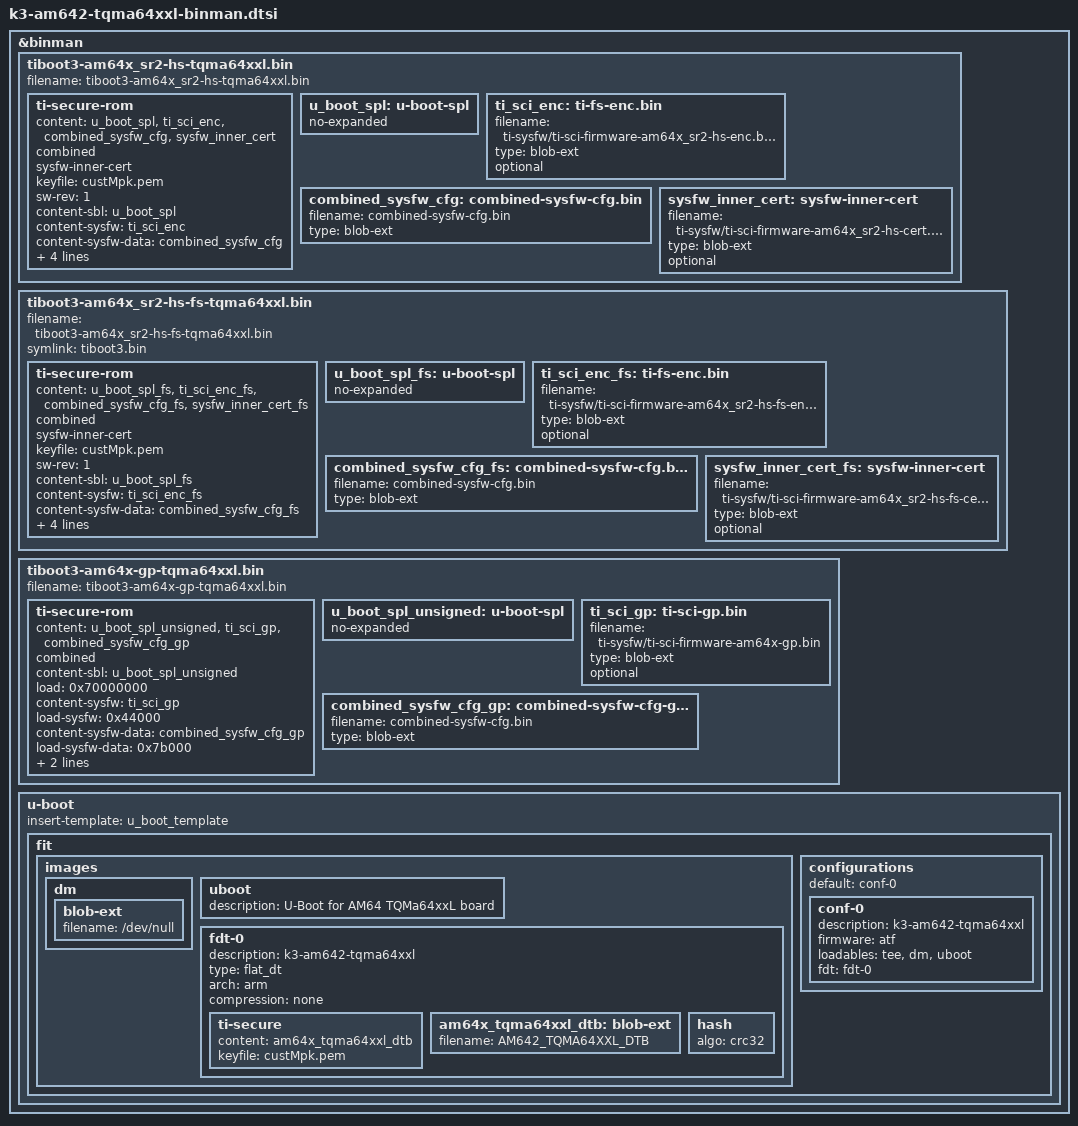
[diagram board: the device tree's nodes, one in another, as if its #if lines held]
// SPDX-License-Identifier: GPL-2.0-or-later
/*
 * Copyright (C) 2022 Texas Instruments Incorporated - https://www.ti.com/
 * Copyright (c) 2023-2025 TQ-Systems GmbH <u-boot@ew.tq-group.com>, D-82229 Seefeld, Germany.
 * Author: Matthias Schiffer
 */

#include "k3-binman.dtsi"

#if IS_ENABLED(CONFIG_TARGET_AM64_R5_TQMA64XXL)

&binman {
	tiboot3-am64x_sr2-hs-tqma64xxl.bin {
		filename = "tiboot3-am64x_sr2-hs-tqma64xxl.bin";
		ti-secure-rom {
			content = <&u_boot_spl>, <&ti_sci_enc>,
				<&combined_sysfw_cfg>, <&sysfw_inner_cert>;
			combined;
			sysfw-inner-cert;
			keyfile = "custMpk.pem";
			sw-rev = <1>;
			content-sbl = <&u_boot_spl>;
			content-sysfw = <&ti_sci_enc>;
			content-sysfw-data = <&combined_sysfw_cfg>;
			content-sysfw-inner-cert = <&sysfw_inner_cert>;
			load = <0x70000000>;
			load-sysfw = <0x44000>;
			load-sysfw-data = <0x7b000>;
		};
		u_boot_spl: u-boot-spl {
			no-expanded;
		};
		ti_sci_enc: ti-fs-enc.bin {
			filename = "ti-sysfw/ti-sci-firmware-am64x_sr2-hs-enc.bin";
			type = "blob-ext";
			optional;
		};
		combined_sysfw_cfg: combined-sysfw-cfg.bin {
			filename = "combined-sysfw-cfg.bin";
			type = "blob-ext";
		};
		sysfw_inner_cert: sysfw-inner-cert {
			filename = "ti-sysfw/ti-sci-firmware-am64x_sr2-hs-cert.bin";
			type = "blob-ext";
			optional;
		};

	};
};

&binman {
	tiboot3-am64x_sr2-hs-fs-tqma64xxl.bin {
		filename = "tiboot3-am64x_sr2-hs-fs-tqma64xxl.bin";
		symlink = "tiboot3.bin";
		ti-secure-rom {
			content = <&u_boot_spl_fs>, <&ti_sci_enc_fs>,
				<&combined_sysfw_cfg_fs>, <&sysfw_inner_cert_fs>;
			combined;
			sysfw-inner-cert;
			keyfile = "custMpk.pem";
			sw-rev = <1>;
			content-sbl = <&u_boot_spl_fs>;
			content-sysfw = <&ti_sci_enc_fs>;
			content-sysfw-data = <&combined_sysfw_cfg_fs>;
			content-sysfw-inner-cert = <&sysfw_inner_cert_fs>;
			load = <0x70000000>;
			load-sysfw = <0x44000>;
			load-sysfw-data = <0x7b000>;
		};
		u_boot_spl_fs: u-boot-spl {
			no-expanded;
		};
		ti_sci_enc_fs: ti-fs-enc.bin {
			filename = "ti-sysfw/ti-sci-firmware-am64x_sr2-hs-fs-enc.bin";
			type = "blob-ext";
			optional;
		};
		combined_sysfw_cfg_fs: combined-sysfw-cfg.bin {
			filename = "combined-sysfw-cfg.bin";
			type = "blob-ext";
		};
		sysfw_inner_cert_fs: sysfw-inner-cert {
			filename = "ti-sysfw/ti-sci-firmware-am64x_sr2-hs-fs-cert.bin";
			type = "blob-ext";
			optional;
		};

	};
};

&binman {
	tiboot3-am64x-gp-tqma64xxl.bin {
		filename = "tiboot3-am64x-gp-tqma64xxl.bin";
		ti-secure-rom {
			content = <&u_boot_spl_unsigned>, <&ti_sci_gp>, <&combined_sysfw_cfg_gp>;
			combined;
			content-sbl = <&u_boot_spl_unsigned>;
			load = <0x70000000>;
			content-sysfw = <&ti_sci_gp>;
			load-sysfw = <0x44000>;
			content-sysfw-data = <&combined_sysfw_cfg_gp>;
			load-sysfw-data = <0x7b000>;
			sw-rev = <1>;
			keyfile = "ti-degenerate-key.pem";
		};
		u_boot_spl_unsigned: u-boot-spl {
			no-expanded;
		};
		ti_sci_gp: ti-sci-gp.bin {
			filename = "ti-sysfw/ti-sci-firmware-am64x-gp.bin";
			type = "blob-ext";
			optional;
		};
		combined_sysfw_cfg_gp: combined-sysfw-cfg-gp.bin {
			filename = "combined-sysfw-cfg.bin";
			type = "blob-ext";
		};
	};
};

#endif

#if IS_ENABLED(CONFIG_TARGET_AM64_A53_TQMA64XXL)

#define AM642_TQMA64XXL_DTB "u-boot.dtb"

&binman {
	u-boot {
		insert-template = <&u_boot_template>;

		fit {
			images {
				dm {
					blob-ext {
						filename = "/dev/null";
					};
				};

				uboot {
					description = "U-Boot for AM64 TQMa64xxL board";
				};

				fdt-0 {
					description = "k3-am642-tqma64xxl";
					type = "flat_dt";
					arch = "arm";
					compression = "none";

					ti-secure {
						content = <&am64x_tqma64xxl_dtb>;
						keyfile = "custMpk.pem";

					};

					am64x_tqma64xxl_dtb: blob-ext {
						filename = AM642_TQMA64XXL_DTB;
					};

					hash {
						algo = "crc32";
					};
				};

			};

			configurations {
				default = "conf-0";

				conf-0 {
					description = "k3-am642-tqma64xxl";
					firmware = "atf";
					loadables = "tee", "dm", "uboot";
					fdt = "fdt-0";
				};
			};
		};
	};
};

#endif
